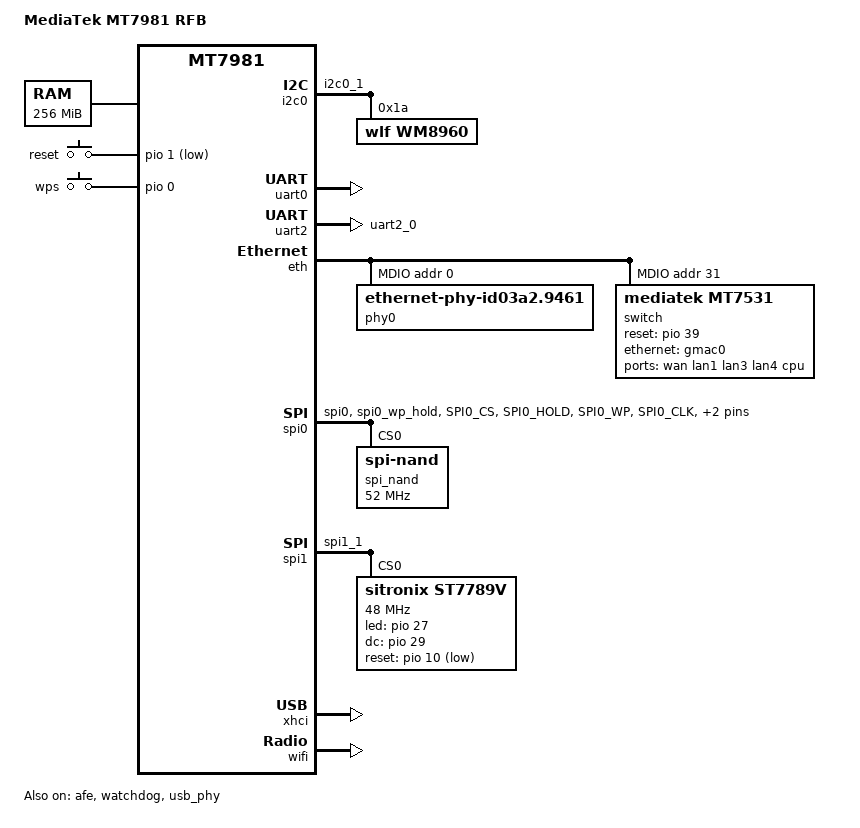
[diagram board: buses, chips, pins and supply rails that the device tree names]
/dts-v1/;
#include "mt7981.dtsi"
/ {
	model = "MediaTek MT7981 RFB";
	compatible = "mediatek,mt7981-spim-snand-rfb";
	chosen {
		bootargs = "console=ttyS0,115200n1 loglevel=8 \
				earlycon=uart8250,mmio32,0x11002000 vt.global_cursor_default=0";
	};

	memory {
		reg = <0 0x40000000 0 0x10000000>;
	};

	gpio-keys {
			compatible = "gpio-keys";
				reset {
					label = "reset";
					linux,code = <KEY_RESTART>;
					gpios = <&pio 1 GPIO_ACTIVE_LOW>;
				};

				wps {
					label = "wps";
					linux,code = <KEY_WPS_BUTTON>;
					gpios = <&pio 0 GPIO_ACTIVE_HIGH>;
				};
	};
	
	nmbm_spim_nand {
		compatible = "generic,nmbm";

		#address-cells = <1>;
		#size-cells = <1>;

		lower-mtd-device = <&spi_nand>;
		forced-create;

		partitions {
			compatible = "fixed-partitions";
			#address-cells = <1>;
			#size-cells = <1>;

			partition@0 {
				label = "bl2";
				reg = <0x00000 0x0100000>;/* 1MB */
				read-only;
			};
			partition@100000 {
				label = "u-boot-env";
				reg = <0x0100000 0x0080000>;
			};
			partition@180000 {
				label = "Factory";
				reg = <0x180000 0x0200000>;
			};
			partition@380000 {
				label = "fip";
				reg = <0x380000 0x0200000>;/* 2MB uboot*/
			};
			partition@580000 {
				label = "ubi";
				reg = <0x580000 0x4000000>;/* 64MB including rootfs/rootfs-data*/
			};

			partition@4580000 {
				label = "Syslog";
				reg = <0x4580000 0x200000>;/* 2MB */
			};
			partition@4780000 {
				label = "CA_WEB";
				reg = <0x4780000 0x20000>;/* 128KB */
			};
			partition@47A0000 {
				label = "CA_VPN";
				reg = <0x47A0000 0x20000>;
			};
			partition@47C0000 {
				label = "CA_uboot";
				reg = <0x47C0000 0x20000>;
			};
			partition@47E0000 {
				label = "Tr069";
				reg = <0x47E0000 0x20000>;
			};
			partition@4800000 {
				label = "Manufacture";
				reg = <0x4800000 0x20000>;
			};
			partition@4820000 {
				label = "Reserve0";
				reg = <0x4820000 0x20000>;
			};
			partition@4840000 {
				label = "Manufacture_bak";
				reg = <0x4840000 0x20000>;
			};

			partition@4860000 {
				label = "Config";
				reg = <0x4860000 0x200000>;/* 2MB */
			};
			partition@4A60000 {
				label = "Backup_config2";
				reg = <0x4A60000 0x200000>;
			};
			partition@4C60000 {
				label = "Backup_config";
				reg = <0x4C60000 0x200000>;
			};
			partition@4E60000 {
				label = "Backup_factory";
				reg = <0x4E60000 0x200000>;
			};
			partition@5060000 {
				label = "SMS";
				reg = <0x5060000 0x200000>;/* 2MB */
			};
			partition@5260000 {
				label = "Reserve1";
				reg = <0x5260000 0x200000>;
			};
			partition@5460000 {
				label = "Reserve2";
				reg = <0x5460000 0x200000>;
			};

			partition@5660000 {
				label = "Backup_firmware";
				reg = <0x5660000 0x1E00000>;/* 30MB */
			};
			partition@7460000 {
				label = "user_data";
				reg = <0x7460000 0x3A0000>;/* 3MB */
			};
		};
	};


};

&afe {
	pinctrl-names = "default";
	pinctrl-0 = <&pcm_pins>;
	status = "okay";
};

&i2c0 {
	pinctrl-names = "default";
	pinctrl-0 = <&i2c_pins>;
	status = "okay";

	wm8960: wm8960@1a {
		compatible = "wlf,wm8960";
		reg = <0x1a>;
	};
};

&uart0 {
	status = "okay";
};

&uart2 {
	pinctrl-names = "default";
	pinctrl-0 = <&uart2_pins>;
	status = "okay";
};

&watchdog {
	status = "okay";
};

&eth {
        status = "okay";

        gmac0: mac@0 {
                compatible = "mediatek,eth-mac";
                reg = <0>;
                phy-mode = "2500base-x";

                fixed-link {
                        speed = <2500>;
                        full-duplex;
                        pause;
                };
        };

	gmac1: mac@1 {
		compatible = "mediatek,eth-mac";
		reg = <1>;
		phy-mode = "gmii";
		phy-handle = <&phy0>;
	};

        mdio: mdio-bus {
                #address-cells = <1>;
                #size-cells = <0>;

		phy0: ethernet-phy@0 {
			compatible = "ethernet-phy-id03a2.9461";
			reg = <0>;
			phy-mode = "gmii";
			nvmem-cells = <&phy_calibration>;
			nvmem-cell-names = "phy-cal-data";
		};

		switch@0 {
                        compatible = "mediatek,mt7531";
                        reg = <31>;
                        reset-gpios = <&pio 39 0>;

                        ports {
                                #address-cells = <1>;
                                #size-cells = <0>;

                                port@0 {
                                        reg = <0>;
                                        label = "wan";
                                };

                                port@1 {
                                        reg = <1>;
                                        label = "lan1";
                                };

                                port@2 {
                                        reg = <2>;
                                        label = "lan3";
                                };

                                port@3 {
                                        reg = <3>;
                                        label = "lan4";
                                };


                                port@6 {
                                        reg = <6>;
                                        label = "cpu";
                                        ethernet = <&gmac0>;
                                        phy-mode = "2500base-x";

                                        fixed-link {
                                                speed = <2500>;
                                                full-duplex;
                                                pause;
                                        };
                                };
                        };
                };
        };
};

&hnat {
	mtketh-wan = "wwan0";
	mtketh-lan = "br0";
	mtketh-max-gmac = <2>;
	status = "disabled";
};

&spi0 {
	pinctrl-names = "default";
	pinctrl-0 = <&spi0_flash_pins>;
	status = "okay";
	spi_nand: spi_nand@0 {
		#address-cells = <1>;
		#size-cells = <1>;
		compatible = "spi-nand";
		reg = <0>;
		spi-max-frequency = <52000000>;
		spi-tx-buswidth = <4>;
		spi-rx-buswidth = <4>;
	};
};

&spi1 {
	pinctrl-names = "default";
	pinctrl-0 = <&spic_pins>;
	status = "okay";

	st7789v: st7789v@0{
        compatible = "sitronix,st7789v";
        reg = <0>;
        status = "okay";
        spi-max-frequency = <48000000>;
        spi-cpol;
        spi-cpha;
        rotate = <180>;
        fps = <60>;
        rgb;
        buswidth = <8>;
		led-gpios = <&pio 27 GPIO_ACTIVE_HIGH>;/*led-gpios : Backlight power en */
		dc-gpios = <&pio 29 GPIO_ACTIVE_HIGH>; /*dc-gpios:RS */
        reset-gpios = <&pio 10 GPIO_ACTIVE_LOW>;

        debug = <0x0>;
    };
};


&pcie {
	pinctrl-names = "default";
	pinctrl-0 = <&pcie_pins>;
	status = "disabled";
};

&pio {

	pcie_pins: pcie-pins {
		mux {
			function = "pcie";
			groups = "pcie_pereset", "pcie_clk", "pcie_wake";
		};
    };
	spic_pins: spi1-pins {
		mux {
			function = "spi";
			groups = "spi1_1";
		};
	};

	i2c_pins: i2c-pins-g1 {
		mux {
			function = "i2c";
			groups = "i2c0_1";
		};
	};

        pcm_pins: pcm-pins-g0 {
                mux {
                        function = "pcm";
                        groups = "pcm";
                };
        };

        pwm0_pin: pwm0-pin-g0 {
                mux {
                        function = "pwm";
                        groups = "pwm0_0";
                };
        };

        pwm1_pin: pwm1-pin-g0 {
                mux {
                        function = "pwm";
                        groups = "pwm1_0";
                };
        };

        pwm2_pin: pwm2-pin {
                mux {
                        function = "pwm";
                        groups = "pwm2";
                };
        };

	spi0_flash_pins: spi0-pins {
		mux {
			function = "spi";
			groups = "spi0", "spi0_wp_hold";
		};

		conf-pu {
			pins = "SPI0_CS", "SPI0_HOLD", "SPI0_WP";
			drive-strength = <MTK_DRIVE_8mA>;
			bias-pull-up = <MTK_PUPD_SET_R1R0_11>;
		};

		conf-pd {
			pins = "SPI0_CLK", "SPI0_MOSI", "SPI0_MISO";
			drive-strength = <MTK_DRIVE_8mA>;
			bias-pull-down = <MTK_PUPD_SET_R1R0_11>;
		};
	};

	uart1_pins: uart1-pins-g1 {
                mux {
                        function = "uart";
                        groups = "uart1_1";
                };
        };

	uart2_pins: uart2-pins-g1 {
		mux {
                        function = "uart";
                        groups = "uart2_0";
                };
        };
};

&usb_phy {
	status = "okay";
};

&xhci {
	status = "okay";
};

&wifi {
	status = "okay";
};
